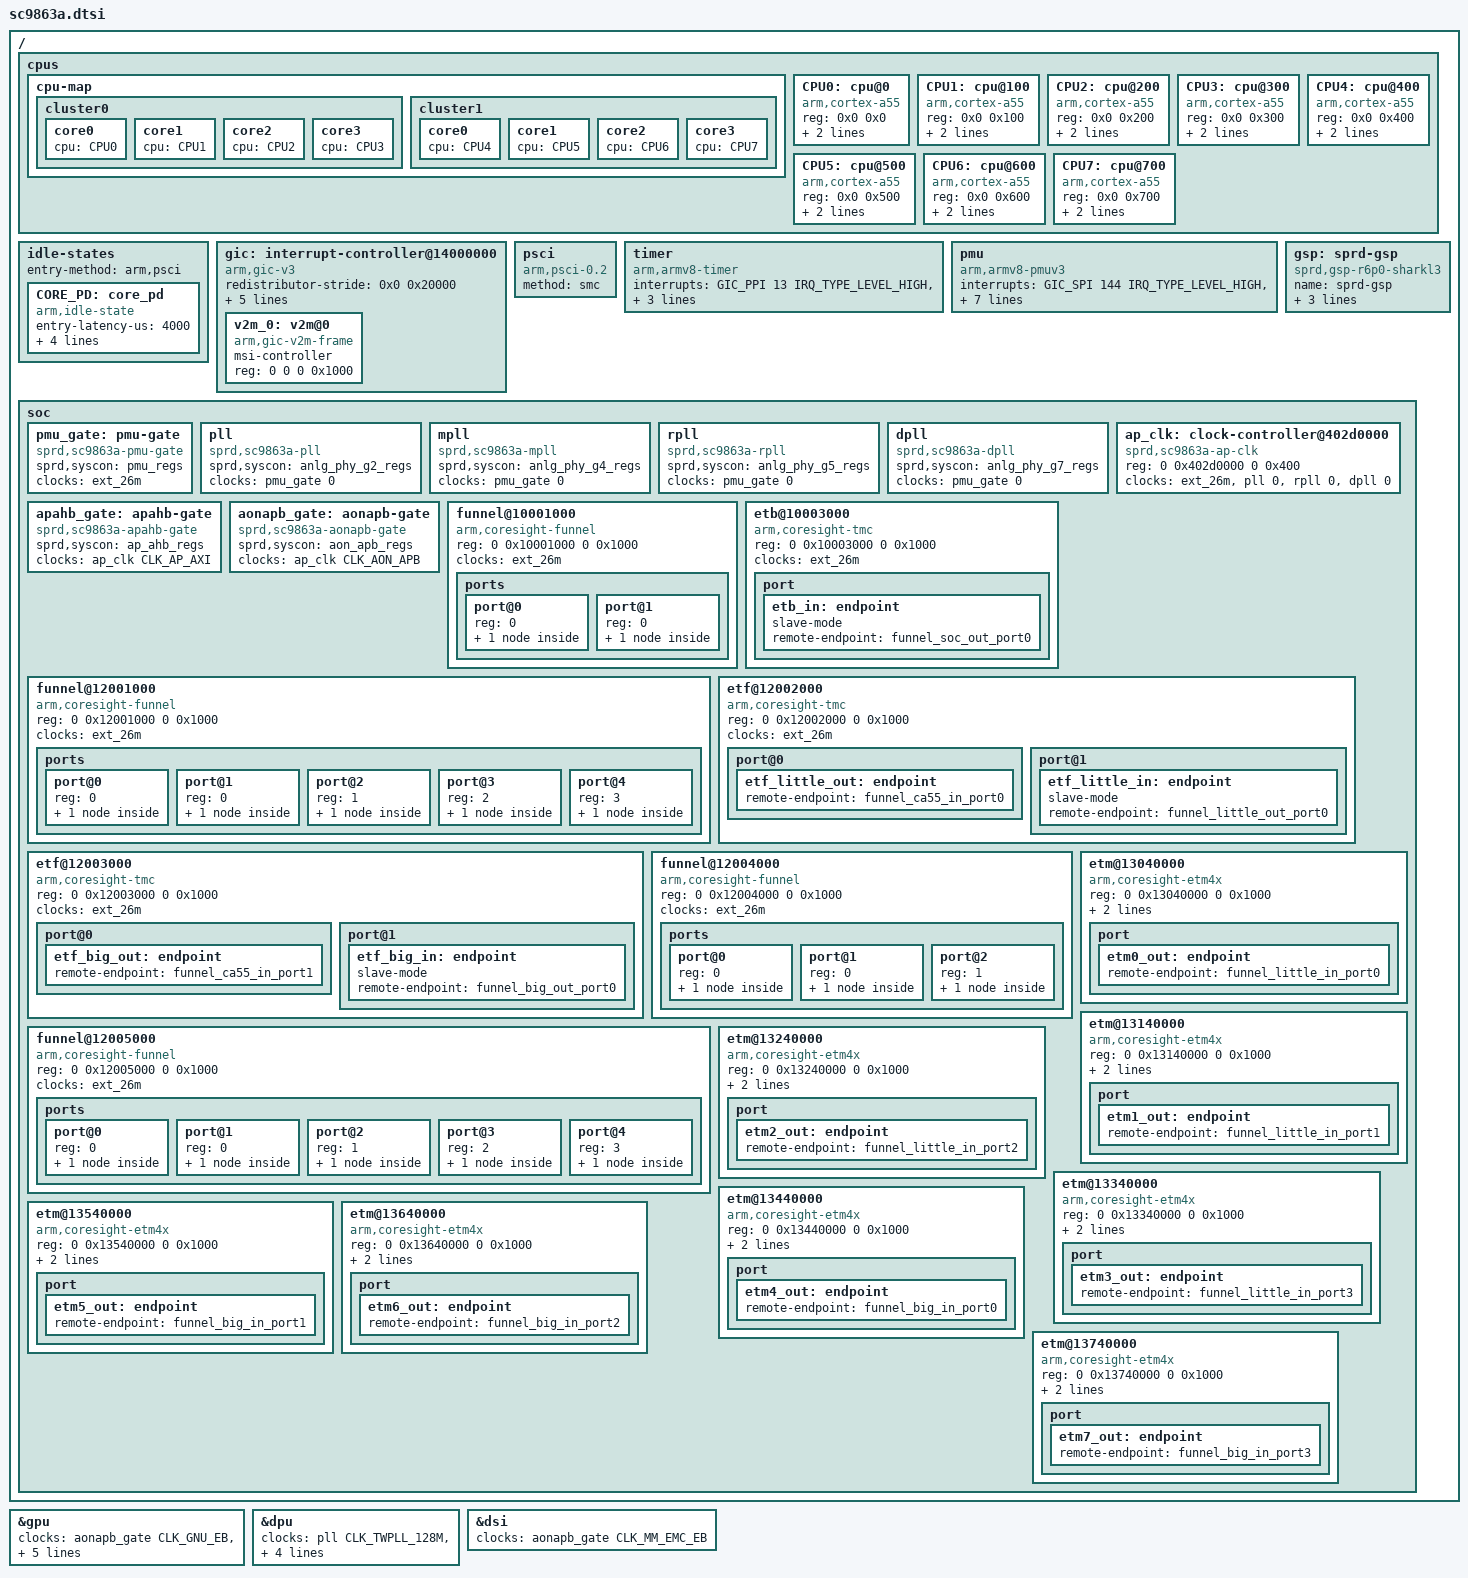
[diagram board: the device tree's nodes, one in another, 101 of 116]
// SPDX-License-Identifier: (GPL-2.0+ OR MIT)
/*
 * Spreadtrum Sharkl3 platform DTS file
 *
 * Copyright (C) 2018, Spreadtrum Communications Inc.
 */

#include <dt-bindings/interrupt-controller/arm-gic.h>
#include <dt-bindings/clock/sprd,sc9863a-clk.h>
#include "sharkl3.dtsi"

/ {
	cpus {
		#address-cells = <2>;
		#size-cells = <0>;

		cpu-map {
			cluster0 {
				core0 {
					cpu = <&CPU0>;
				};
				core1 {
					cpu = <&CPU1>;
				};
				core2 {
					cpu = <&CPU2>;
				};
				core3 {
					cpu = <&CPU3>;
				};
			};

			cluster1 {
				core0 {
					cpu = <&CPU4>;
				};
				core1 {
					cpu = <&CPU5>;
				};
				core2 {
					cpu = <&CPU6>;
				};
				core3 {
					cpu = <&CPU7>;
				};
			};
		};

		CPU0: cpu@0 {
			device_type = "cpu";
			compatible = "arm,cortex-a55","arm,armv8";
			reg = <0x0 0x0>;
			enable-method = "psci";
			cpu-idle-states = <&CORE_PD>;
		};

		CPU1: cpu@100 {
			device_type = "cpu";
			compatible = "arm,cortex-a55","arm,armv8";
			reg = <0x0 0x100>;
			enable-method = "psci";
			cpu-idle-states = <&CORE_PD>;
		};

		CPU2: cpu@200 {
			device_type = "cpu";
			compatible = "arm,cortex-a55","arm,armv8";
			reg = <0x0 0x200>;
			enable-method = "psci";
			cpu-idle-states = <&CORE_PD>;
		};

		CPU3: cpu@300 {
			device_type = "cpu";
			compatible = "arm,cortex-a55","arm,armv8";
			reg = <0x0 0x300>;
			enable-method = "psci";
			cpu-idle-states = <&CORE_PD>;
		};

		CPU4: cpu@400 {
			device_type = "cpu";
			compatible = "arm,cortex-a55","arm,armv8";
			reg = <0x0 0x400>;
			enable-method = "psci";
			cpu-idle-states = <&CORE_PD>;
		};

		CPU5: cpu@500 {
			device_type = "cpu";
			compatible = "arm,cortex-a55","arm,armv8";
			reg = <0x0 0x500>;
			enable-method = "psci";
			cpu-idle-states = <&CORE_PD>;
		};

		CPU6: cpu@600 {
			device_type = "cpu";
			compatible = "arm,cortex-a55","arm,armv8";
			reg = <0x0 0x600>;
			enable-method = "psci";
			cpu-idle-states = <&CORE_PD>;
		};

		CPU7: cpu@700 {
			device_type = "cpu";
			compatible = "arm,cortex-a55","arm,armv8";
			reg = <0x0 0x700>;
			enable-method = "psci";
			cpu-idle-states = <&CORE_PD>;
		};
	};

	idle-states {
		entry-method = "arm,psci";
		CORE_PD: core_pd {
			compatible = "arm,idle-state";
			entry-latency-us = <4000>;
			exit-latency-us = <4000>;
			min-residency-us = <10000>;
			local-timer-stop;
			arm,psci-suspend-param = <0x00010000>;
		};
	};

	gic: interrupt-controller@14000000 {
		compatible = "arm,gic-v3";
		#interrupt-cells = <3>;
		#address-cells = <2>;
		#size-cells = <2>;
		ranges;
		redistributor-stride = <0x0 0x20000>;	/* 128KB stride */
		#redistributor-regions = <1>;
		interrupt-controller;
		reg = <0x0 0x14000000 0 0x20000>,	/* GICD */
			<0x0 0x14040000 0 0x100000>;	/* GICR */
		interrupts = <1 9 4>;
		v2m_0: v2m@0 {
			compatible = "arm,gic-v2m-frame";
			msi-controller;
			reg = <0 0 0 0x1000>;
		};
	};

	psci {
		compatible = "arm,psci-0.2";
		method = "smc";
	};


	timer {
		compatible = "arm,armv8-timer";
		interrupts = <GIC_PPI 13 IRQ_TYPE_LEVEL_HIGH>, /* Physical Secure PPI */
			     <GIC_PPI 14 IRQ_TYPE_LEVEL_HIGH>, /* Physical Non-Secure PPI */
			     <GIC_PPI 11 IRQ_TYPE_LEVEL_HIGH>, /* Virtual PPI */
			     <GIC_PPI 10 IRQ_TYPE_LEVEL_HIGH>; /* Hipervisor PPI */
	};

	pmu {
		compatible = "arm,armv8-pmuv3";
		interrupts = <GIC_SPI 144 IRQ_TYPE_LEVEL_HIGH>,
				<GIC_SPI 145 IRQ_TYPE_LEVEL_HIGH>,
				<GIC_SPI 146 IRQ_TYPE_LEVEL_HIGH>,
				<GIC_SPI 147 IRQ_TYPE_LEVEL_HIGH>,
				<GIC_SPI 148 IRQ_TYPE_LEVEL_HIGH>,
				<GIC_SPI 149 IRQ_TYPE_LEVEL_HIGH>,
				<GIC_SPI 150 IRQ_TYPE_LEVEL_HIGH>,
				<GIC_SPI 151 IRQ_TYPE_LEVEL_HIGH>;
	};

	gsp: sprd-gsp {
		compatible = "sprd,gsp-r6p0-sharkl3";
		name = "sprd-gsp";
		core-cnt = <1>;
		io-cnt = <7>;
		cores = <&gsp_core0>;
		/*power-domains = <&disp_pd>;*/
	};

	soc {
		pmu_gate: pmu-gate {
			compatible = "sprd,sc9863a-pmu-gate";
			sprd,syscon = <&pmu_regs>; /* 0x402b0000 */
			clocks = <&ext_26m>;
			#clock-cells = <1>;
		};

		pll: pll {
			compatible = "sprd,sc9863a-pll";
			sprd,syscon = <&anlg_phy_g2_regs>; /* 0x40353000 */
			clocks = <&pmu_gate 0>;
			#clock-cells = <1>;
		};

		mpll: mpll {
			compatible = "sprd,sc9863a-mpll";
			sprd,syscon = <&anlg_phy_g4_regs>; /* 0x40359000 */
			clocks = <&pmu_gate 0>;
			#clock-cells = <1>;
		};

		rpll: rpll {
			compatible = "sprd,sc9863a-rpll";
			sprd,syscon = <&anlg_phy_g5_regs>; /* 0x4035c000 */
			clocks = <&pmu_gate 0>;
			#clock-cells = <1>;
		};

		dpll: dpll {
			compatible = "sprd,sc9863a-dpll";
			sprd,syscon = <&anlg_phy_g7_regs>; /* 0x40363000 */
			clocks = <&pmu_gate 0>;
			#clock-cells = <1>;
		};

		ap_clk: clock-controller@402d0000 {
			compatible = "sprd,sc9863a-ap-clk";
			reg = <0 0x402d0000 0 0x400>;
			clocks = <&ext_26m>, <&pll 0>,
				 <&rpll 0>, <&dpll 0>;
			#clock-cells = <1>;
		};

		apahb_gate: apahb-gate {
			compatible = "sprd,sc9863a-apahb-gate";
			sprd,syscon = <&ap_ahb_regs>; /* 0x20e00000 */
			clocks = <&ap_clk CLK_AP_AXI>;
			#clock-cells = <1>;
		};

		aonapb_gate: aonapb-gate {
			compatible = "sprd,sc9863a-aonapb-gate";
			sprd,syscon = <&aon_apb_regs>; /* 0x40e00000 */
			clocks = <&ap_clk CLK_AON_APB>;
			#clock-cells = <1>;
		};

		funnel@10001000 {
			compatible = "arm,coresight-funnel", "arm,primecell";
			reg = <0 0x10001000 0 0x1000>;
			clocks = <&ext_26m>;
			clock-names = "apb_pclk";
			ports {
				#address-cells = <1>;
				#size-cells = <0>;

				port@0 {
					reg = <0>;
					funnel_soc_out_port0: endpoint {
						remote-endpoint = <&etb_in>;
					};
				};

				port@1 {
					reg = <0>;
					funnel_soc_in_port0: endpoint {
						slave-mode;
						remote-endpoint = <&funnel_ca55_out_port0>;
					};
				};
			};
		};

		etb@10003000 {
			compatible = "arm,coresight-tmc", "arm,primecell";
			reg = <0 0x10003000 0 0x1000>;
			clocks = <&ext_26m>;
			clock-names = "apb_pclk";
			port {
				etb_in: endpoint {
					slave-mode;
					remote-endpoint = <&funnel_soc_out_port0>;
				};
			};
		};

		funnel@12001000 {
			compatible = "arm,coresight-funnel", "arm,primecell";
			reg = <0 0x12001000 0 0x1000>;
			clocks = <&ext_26m>;
			clock-names = "apb_pclk";
			ports {
				#address-cells = <1>;
				#size-cells = <0>;

				port@0 {
					reg = <0>;
					funnel_little_out_port0: endpoint {
						remote-endpoint = <&etf_little_in>;
					};
				};

				port@1 {
					reg = <0>;
					funnel_little_in_port0: endpoint {
						slave-mode;
						remote-endpoint = <&etm0_out>;
					};
				};

				port@2 {
					reg = <1>;
					funnel_little_in_port1: endpoint {
						slave-mode;
						remote-endpoint = <&etm1_out>;
					};
				};

				port@3 {
					reg = <2>;
					funnel_little_in_port2: endpoint {
						slave-mode;
						remote-endpoint = <&etm2_out>;
					};
				};

				port@4 {
					reg = <3>;
					funnel_little_in_port3: endpoint {
						slave-mode;
						remote-endpoint = <&etm3_out>;
					};
				};
			};
		};

		etf@12002000 {
			compatible = "arm,coresight-tmc", "arm,primecell";
			reg = <0 0x12002000 0 0x1000>;
			clocks = <&ext_26m>;
			clock-names = "apb_pclk";

			port@0 {
				etf_little_out: endpoint {
					remote-endpoint = <&funnel_ca55_in_port0>;
				};
			};

			port@1 {
				etf_little_in: endpoint {
					slave-mode;
					remote-endpoint = <&funnel_little_out_port0>;
				};
			};
		};

		etf@12003000 {
			compatible = "arm,coresight-tmc", "arm,primecell";
			reg = <0 0x12003000 0 0x1000>;
			clocks = <&ext_26m>;
			clock-names = "apb_pclk";

			port@0 {
				etf_big_out: endpoint {
					remote-endpoint = <&funnel_ca55_in_port1>;
				};
			};

			port@1 {
				etf_big_in: endpoint {
					slave-mode;
					remote-endpoint = <&funnel_big_out_port0>;
				};
			};
		};

		funnel@12004000 {
			compatible = "arm,coresight-funnel", "arm,primecell";
			reg = <0 0x12004000 0 0x1000>;
			clocks = <&ext_26m>;
			clock-names = "apb_pclk";

			ports {
				#address-cells = <1>;
				#size-cells = <0>;

				port@0 {
					reg = <0>;
					funnel_ca55_out_port0: endpoint {
						remote-endpoint = <&funnel_soc_in_port0>;
					};
				};

				port@1 {
					reg = <0>;
					funnel_ca55_in_port0: endpoint {
						slave-mode;
						remote-endpoint = <&etf_little_out>;
					};
				};

				port@2 {
					reg = <1>;
					funnel_ca55_in_port1: endpoint {
						slave-mode;
						remote-endpoint = <&etf_big_out>;
					};
				};
			};
		};

		funnel@12005000 {
			compatible = "arm,coresight-funnel", "arm,primecell";
			reg = <0 0x12005000 0 0x1000>;
			clocks = <&ext_26m>;
			clock-names = "apb_pclk";

			ports {
				#address-cells = <1>;
				#size-cells = <0>;

				port@0 {
					reg = <0>;
					funnel_big_out_port0: endpoint {
						remote-endpoint = <&etf_big_in>;
					};
				};

				port@1 {
					reg = <0>;
					funnel_big_in_port0: endpoint {
						slave-mode;
						remote-endpoint = <&etm4_out>;
					};
				};

				port@2 {
					reg = <1>;
					funnel_big_in_port1: endpoint {
						slave-mode;
						remote-endpoint = <&etm5_out>;
					};
				};

				port@3 {
					reg = <2>;
					funnel_big_in_port2: endpoint {
						slave-mode;
						remote-endpoint = <&etm6_out>;
					};
				};

				port@4 {
					reg = <3>;
					funnel_big_in_port3: endpoint {
						slave-mode;
						remote-endpoint = <&etm7_out>;
					};
				};
			};
		};

		etm@13040000 {
			compatible = "arm,coresight-etm4x", "arm,primecell";
			reg = <0 0x13040000 0 0x1000>;
			cpu = <&CPU0>;
			clocks = <&ext_26m>;
			clock-names = "apb_pclk";

			port {
				etm0_out: endpoint {
					remote-endpoint = <&funnel_little_in_port0>;
				};
			};
		};

		etm@13140000 {
			compatible = "arm,coresight-etm4x", "arm,primecell";
			reg = <0 0x13140000 0 0x1000>;
			cpu = <&CPU1>;
			clocks = <&ext_26m>;
			clock-names = "apb_pclk";

			port {
				etm1_out: endpoint {
					remote-endpoint = <&funnel_little_in_port1>;
				};
			};
		};

		etm@13240000 {
			compatible = "arm,coresight-etm4x", "arm,primecell";
			reg = <0 0x13240000 0 0x1000>;
			cpu = <&CPU2>;
			clocks = <&ext_26m>;
			clock-names = "apb_pclk";

			port {
				etm2_out: endpoint {
					remote-endpoint = <&funnel_little_in_port2>;
				};
			};
		};

		etm@13340000 {
			compatible = "arm,coresight-etm4x", "arm,primecell";
			reg = <0 0x13340000 0 0x1000>;
			cpu = <&CPU3>;
			clocks = <&ext_26m>;
			clock-names = "apb_pclk";

			port {
				etm3_out: endpoint {
					remote-endpoint = <&funnel_little_in_port3>;
				};
			};
		};

		etm@13440000 {
			compatible = "arm,coresight-etm4x", "arm,primecell";
			reg = <0 0x13440000 0 0x1000>;
			cpu = <&CPU4>;
			clocks = <&ext_26m>;
			clock-names = "apb_pclk";

			port {
				etm4_out: endpoint {
					remote-endpoint = <&funnel_big_in_port0>;
				};
			};
		};

		etm@13540000 {
			compatible = "arm,coresight-etm4x", "arm,primecell";
			reg = <0 0x13540000 0 0x1000>;
			cpu = <&CPU5>;
			clocks = <&ext_26m>;
			clock-names = "apb_pclk";

			port {
				etm5_out: endpoint {
					remote-endpoint = <&funnel_big_in_port1>;
				};
			};
		};

		etm@13640000 {
			compatible = "arm,coresight-etm4x", "arm,primecell";
			reg = <0 0x13640000 0 0x1000>;
			cpu = <&CPU6>;
			clocks = <&ext_26m>;
			clock-names = "apb_pclk";

			port {
				etm6_out: endpoint {
					remote-endpoint = <&funnel_big_in_port2>;
				};
			};
		};

		etm@13740000 {
			compatible = "arm,coresight-etm4x", "arm,primecell";
			reg = <0 0x13740000 0 0x1000>;
			cpu = <&CPU7>;
			clocks = <&ext_26m>;
			clock-names = "apb_pclk";

			port {
				etm7_out: endpoint {
					remote-endpoint = <&funnel_big_in_port3>;
				};
			};
		};

	};
};

&gpu {
	clocks = <&aonapb_gate CLK_GNU_EB>,
	<&ap_clk CLK_GPU_CORE>,<&ap_clk CLK_GPU_SOC>,
	<&pll CLK_TWPLL_153M6>, <&pll CLK_TWPLL_192M>,
	<&pll CLK_TWPLL_256M>, <&pll CLK_TWPLL_307M2>,
	<&pll CLK_TWPLL_384M>, <&pll CLK_TWPLL_512M>,
	<&pll CLK_GPLL>;
	};

&dpu {
	clock-names = "clk_src_128m",
			"clk_src_153m6",
			"clk_src_192m",
			"clk_src_256m",
			"clk_src_384m",
			"clk_dpu_core",
			"clk_dpu_dpi",
			"clk_aon_apb_disp_eb";

	clocks = <&pll CLK_TWPLL_128M>,
		<&pll CLK_TWPLL_153M6>,
		<&pll CLK_TWPLL_192M>,
		<&pll CLK_TWPLL_256M>,
		<&pll CLK_TWPLL_384M>,
		<&ap_clk CLK_DPU>,
		<&ap_clk CLK_DPU_DPI>,
		<&aonapb_gate CLK_MM_EMC_EB>;
};

&dsi {
	clock-names = "clk_aon_apb_disp_eb";
	clocks = <&aonapb_gate CLK_MM_EMC_EB>;
};
